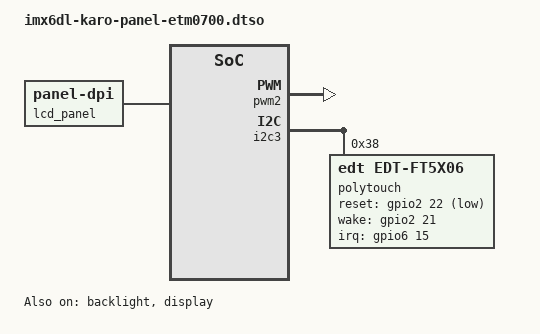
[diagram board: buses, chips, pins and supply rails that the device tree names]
// SPDX-License-Identifier: (GPL-2.0 OR MIT)
/*
 * Copyright 2026 Ka-Ro electronics GmbH
 *
 * EDT ETM0700G0DH6 800x480 RGB panel on the MB7 LCD connector.
 */

/dts-v1/;
/plugin/;

#include <dt-bindings/gpio/gpio.h>
#include <dt-bindings/interrupt-controller/irq.h>
#include "imx6dl-pinfunc.h"

&{/} {
	chosen {
		overlays {
			karo-panel-etm0700;
		};
	};
};

&backlight {
	status = "okay";
};

&display {
	status = "okay";
};

&pwm2 {
	status = "okay";
};

&lcd_panel {
	compatible = "panel-dpi";
	data-mapping = "rgb24";
	width-mm = <152>;
	height-mm = <91>;
	status = "okay";

	panel-timing {
		clock-frequency = <33264000>;
		hactive = <800>;
		vactive = <480>;
		hback-porch = <88>;
		hsync-len = <128>;
		hfront-porch = <40>;
		vback-porch = <33>;
		vsync-len = <2>;
		vfront-porch = <10>;
		hsync-active = <0>;
		vsync-active = <0>;
		de-active = <1>;
		pixelclk-active = <0>;
	};
};

/* FT5x06 touch on the MB7 panel connector */
&i2c3 {
	polytouch: polytouch@38 {
		compatible = "edt,edt-ft5x06";
		reg = <0x38>;
		pinctrl-names = "default";
		pinctrl-0 = <&pinctrl_edt_ft5x06>;
		interrupt-parent = <&gpio6>;
		interrupts = <15 IRQ_TYPE_EDGE_FALLING>;
		reset-gpios = <&gpio2 22 GPIO_ACTIVE_LOW>;
		wake-gpios = <&gpio2 21 GPIO_ACTIVE_HIGH>;
		wakeup-source;
	};
};

&iomuxc {
	pinctrl_edt_ft5x06: edt-ft5x06grp {
		fsl,pins = <
			MX6QDL_PAD_NANDF_CS2__GPIO6_IO15	0x1b0b0
			MX6QDL_PAD_EIM_A16__GPIO2_IO22		0x1b0b0
			MX6QDL_PAD_EIM_A17__GPIO2_IO21		0x1b0b0
		>;
	};
};
